# USCI_B3__SPI_Mode_1 register map
Vendor: Texas Instruments
Peripheral module from a debugger description file (folder msp430).
Registers are 8-bit, access not given, no defined reset value unless marked. A register's access mark holds for its fields unless they carry their own. Offsets are as the file gives them; lines under a group give offsets from that group; [hi:lo] are bit positions; {n}, {i} and the like mark numbered series; 'fields as' and 'values as' point back to an identical list; <NAME> marks a mode.

## USCI_B3_SPI_Mode
0x6A0 UCB3CTLW0__SPI 16-bit — USCI B3 Control Word Register 0
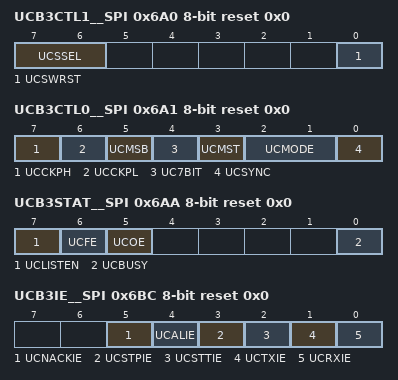
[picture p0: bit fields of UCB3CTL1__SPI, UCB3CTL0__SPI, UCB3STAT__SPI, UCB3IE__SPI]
0x6A0 UCB3CTL1__SPI rw reset 0x0 — USCI B3 Control Register 1
  [7:6] UCSSEL — USCI 1 Clock Source Select 1
    {v}=USCI 0 Clock Source: {v} (v=0..3)
  [0] UCSWRST — USCI Software Reset
0x6A1 UCB3CTL0__SPI rw reset 0x0 — USCI B3 Control Register 0
  [7] UCCKPH — Sync. Mode: Clock Phase
  [6] UCCKPL — Sync. Mode: Clock Polarity
  [5] UCMSB — Sync. Mode: MSB first 0:LSB / 1:MSB
  [4] UC7BIT — Sync. Mode: Data Bits 0:8-bits / 1:7-bits
  [3] UCMST — Sync. Mode: Master Select
  [2:1] UCMODE — Sync. Mode: USCI Mode 1
    {v}=Sync. Mode: USCI Mode: {v} (v=0..3)
  [0] UCSYNC — Sync-Mode 0:UART-Mode / 1:SPI-Mode
0x6A6 UCB3BRW__SPI 16-bit — USCI B3 Baud Word Rate 0
0x6A6 UCB3BR0__SPI — USCI B3 Baud Rate 0
0x6A7 UCB3BR1__SPI — USCI B3 Baud Rate 1
0x6AA UCB3STAT__SPI rw reset 0x0 — USCI B3 Status Register
  [7] UCLISTEN — USCI Listen mode
  [6] UCFE — USCI Frame Error Flag
  [5] UCOE — USCI Overrun Error Flag
  [0] UCBUSY — USCI Busy Flag
0x6AC UCB3RXBUF__SPI — USCI B3 Receive Buffer
0x6AE UCB3TXBUF__SPI — USCI B3 Transmit Buffer
0x6BC UCB3ICTL__SPI 16-bit — USCI B3 Interrupt Enable Register
0x6BC UCB3IE__SPI rw reset 0x0 — USCI B3 Interrupt Enable Register
  [5] UCNACKIE — NACK Condition interrupt enable
  [4] UCALIE — Arbitration Lost interrupt enable
  [3] UCSTPIE — STOP Condition interrupt enable
  [2] UCSTTIE — START Condition interrupt enable
  [1] UCTXIE — USCI Transmit Interrupt Enable
  [0] UCRXIE — USCI Receive Interrupt Enable
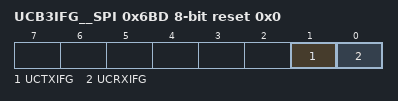
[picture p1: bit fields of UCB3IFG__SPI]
0x6BD UCB3IFG__SPI rw reset 0x0 — USCI B3 Interrupt Flags Register
  [1] UCTXIFG — USCI Transmit Interrupt Flag
  [0] UCRXIFG — USCI Receive Interrupt Flag
0x6BE UCB3IV__SPI 16-bit — USCI B3 Interrupt Vector Register
